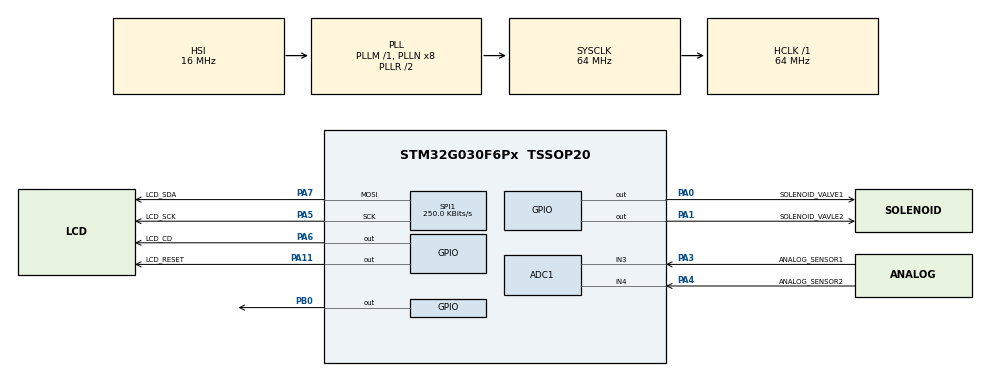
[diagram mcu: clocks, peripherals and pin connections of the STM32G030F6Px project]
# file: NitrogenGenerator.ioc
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ADC1.Channel-3\#ChannelRegularConversion=ADC_CHANNEL_3
ADC1.ClockPrescaler=ADC_CLOCK_ASYNC_DIV256
ADC1.ContinuousConvMode=DISABLE
ADC1.DMAContinuousRequests=DISABLE
ADC1.DiscontinuousConvMode=DISABLE
ADC1.EOCSelection=ADC_EOC_SINGLE_CONV
ADC1.NbrOfConversion=1
ADC1.NbrOfConversionFlag=1
ADC1.Rank-3\#ChannelRegularConversion=1
ADC1.SamplingTime-3\#ChannelRegularConversion=ADC_SAMPLINGTIME_COMMON_1
ADC1.SamplingTimeCommon1=ADC_SAMPLETIME_160CYCLES_5
ADC1.SamplingTimeCommon2=ADC_SAMPLETIME_160CYCLES_5
ADC1.SelectedChannel=ADC_CHANNEL_3|ADC_CHANNEL_4
ADC1.Sequencer=FULLY_CONFIGURABLE
ADC1.TriggerFrequencyMode=ADC_TRIGGER_FREQ_LOW
ADC1.master=1
Dma.ADC1.0.Direction=DMA_PERIPH_TO_MEMORY
Dma.ADC1.0.EventEnable=DISABLE
Dma.ADC1.0.Instance=DMA1_Channel1
Dma.ADC1.0.MemDataAlignment=DMA_MDATAALIGN_WORD
Dma.ADC1.0.MemInc=DMA_MINC_ENABLE
Dma.ADC1.0.Mode=DMA_NORMAL
Dma.ADC1.0.PeriphDataAlignment=DMA_PDATAALIGN_WORD
Dma.ADC1.0.PeriphInc=DMA_PINC_DISABLE
Dma.ADC1.0.Polarity=HAL_DMAMUX_REQ_GEN_RISING
Dma.ADC1.0.Priority=DMA_PRIORITY_LOW
Dma.ADC1.0.RequestNumber=1
Dma.ADC1.0.SignalID=NONE
Dma.ADC1.0.SyncEnable=DISABLE
Dma.ADC1.0.SyncPolarity=HAL_DMAMUX_SYNC_NO_EVENT
Dma.ADC1.0.SyncRequestNumber=1
Dma.ADC1.0.SyncSignalID=NONE
Dma.Request0=ADC1
Mcu.Family=STM32G0
Mcu.Name=STM32G030F6Px
Mcu.Package=TSSOP20
NVIC.ADC1_IRQn=true\:0\:0\:false\:false\:true\:true\:true\:true
NVIC.DMA1_Channel1_IRQn=true\:0\:0\:false\:false\:true\:false\:true\:true
NVIC.TIM1_BRK_UP_TRG_COM_IRQn=true\:0\:0\:false\:false\:true\:true\:true\:true
NVIC.TIM1_CC_IRQn=true\:0\:0\:false\:false\:true\:true\:true\:true
NVIC.TIM3_IRQn=true\:0\:0\:false\:false\:true\:true\:true\:true
PA0.GPIO_Label=SOLENOID_VALVE1
PA0.Signal=GPIO_Output
PA1.GPIO_Label=SOLENOID_VAVLE2
PA1.Signal=GPIO_Output
PA11\ [PA9].GPIO_Label=LCD_RESET
PA11\ [PA9].Signal=GPIO_Output
PA13.Mode=Serial_Wire
PA13.Signal=SYS_SWDIO
PA14-BOOT0.Mode=Serial_Wire
PA14-BOOT0.Signal=SYS_SWCLK
PA14-BOOT0__PA15.StandardMode=true
PA3.GPIO_Label=ANALOG_SENSOR1
PA3.Mode=IN3
PA3.Signal=ADC1_IN3
PA4.GPIO_Label=ANALOG_SENSOR2
PA4.Mode=IN4
PA4.Signal=ADC1_IN4
PA5.GPIO_Label=LCD_SCK
PA5.Mode=TX_Only_Simplex_Unidirect_Master
PA5.Signal=SPI1_SCK
PA6.GPIO_Label=LCD_CD
PA6.Signal=GPIO_Output
PA7.GPIO_Label=LCD_SDA
PA7.Mode=TX_Only_Simplex_Unidirect_Master
PA7.Signal=SPI1_MOSI
PB0.Signal=GPIO_Output
PB0__PB1__PB2__PA8.StandardMode=false
PB3__PB4__PB5__PB6.StandardMode=true
PB7__PB8.StandardMode=true
PC14-OSC32_IN\ (PC14)__PB9.StandardMode=true
ProjectManager.HeapSize=0x200
ProjectManager.StackSize=0x400
ProjectManager.TargetToolchain=CMake
RCC.ADCFreq_Value=64000000
RCC.AHBFreq_Value=64000000
RCC.CortexFreq_Value=64000000
RCC.EXTERNAL_CLOCK_VALUE=12288000
RCC.HCLKFreq_Value=64000000
RCC.HSE_VALUE=8000000
RCC.HSI_VALUE=16000000
RCC.LSE_VALUE=32768
RCC.PLLP=RCC_PLLP_DIV4
RCC.SYSCLKFreq_VALUE=64000000
RCC.SYSCLKSource=RCC_SYSCLKSOURCE_PLLCLK
RCC.VCOOutputFreq_Value=128000000
SPI1.BaudRatePrescaler=SPI_BAUDRATEPRESCALER_256
SPI1.CalculateBaudRate=250.0 KBits/s
SPI1.Direction=SPI_DIRECTION_2LINES
SPI1.Mode=SPI_MODE_MASTER
SPI1.VirtualType=VM_MASTER
TIM1.AutoReloadPreload=TIM_AUTORELOAD_PRELOAD_ENABLE
TIM1.Period=64000
TIM1.Prescaler=100
TIM3.AutoReloadPreload=TIM_AUTORELOAD_PRELOAD_ENABLE
TIM3.Period=64000
TIM3.Prescaler=1000
VP_TIM1_VS_ClockSourceINT.Mode=Internal
VP_TIM3_VS_ClockSourceINT.Mode=Internal
board=custom

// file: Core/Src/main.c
/* USER CODE BEGIN Header */
/**
  ******************************************************************************
  * @file           : main.c
  * @brief          : Main program body
  ******************************************************************************
  * @attention
  *
  * Copyright (c) 2025 STMicroelectronics.
  * All rights reserved.
  *
  * This software is licensed under terms that can be found in the LICENSE file
  * in the root directory of this software component.
  * If no LICENSE file comes with this software, it is provided AS-IS.
  *
  ******************************************************************************
  */
/* USER CODE END Header */
#include "main.h"

/* USER CODE BEGIN Includes */
#include <string.h>
#include "../../screen.h"
/* USER CODE END Includes */

ADC_HandleTypeDef hadc1;
DMA_HandleTypeDef hdma_adc1;

SPI_HandleTypeDef hspi1;

TIM_HandleTypeDef htim1;
TIM_HandleTypeDef htim3;

void SystemClock_Config(void);
static void MX_GPIO_Init(void);
static void MX_DMA_Init(void);
static void MX_ADC1_Init(void);
static void MX_SPI1_Init(void);
static void MX_TIM1_Init(void);
static void MX_TIM3_Init(void);

int main(void)
{

  /* MCU Configuration--------------------------------------------------------*/

  /* Reset of all peripherals, Initializes the Flash interface and the Systick. */
  HAL_Init();

  /* Configure the system clock */
  SystemClock_Config();

  /* Initialize all configured peripherals */
  MX_GPIO_Init();
  MX_DMA_Init();
  MX_ADC1_Init();
  MX_SPI1_Init();
  MX_TIM1_Init();
  MX_TIM3_Init();
  /* USER CODE BEGIN 2 */
  screen_init();
  HAL_ADCEx_Calibration_Start(&hadc1);
  HAL_TIM_Base_Start_IT(&htim1);
  HAL_TIM_Base_Start_IT(&htim3);
  /* USER CODE END 2 */

  /* Infinite loop */
  /* USER CODE BEGIN WHILE */
  while (1)
  {
    __WFI();
    /* USER CODE END WHILE */

  }
}

void SystemClock_Config(void)
{
  RCC_OscInitTypeDef RCC_OscInitStruct = {0};
  RCC_ClkInitTypeDef RCC_ClkInitStruct = {0};

  /** Configure the main internal regulator output voltage
  */
  HAL_PWREx_ControlVoltageScaling(PWR_REGULATOR_VOLTAGE_SCALE1);

  /** Initializes the RCC Oscillators according to the specified parameters
  * in the RCC_OscInitTypeDef structure.
  */
  RCC_OscInitStruct.OscillatorType = RCC_OSCILLATORTYPE_HSI;
  RCC_OscInitStruct.HSIState = RCC_HSI_ON;
  RCC_OscInitStruct.HSIDiv = RCC_HSI_DIV1;
  RCC_OscInitStruct.HSICalibrationValue = RCC_HSICALIBRATION_DEFAULT;
  RCC_OscInitStruct.PLL.PLLState = RCC_PLL_ON;
  RCC_OscInitStruct.PLL.PLLSource = RCC_PLLSOURCE_HSI;
  RCC_OscInitStruct.PLL.PLLM = RCC_PLLM_DIV1;
  RCC_OscInitStruct.PLL.PLLN = 8;
  RCC_OscInitStruct.PLL.PLLP = RCC_PLLP_DIV4;
  RCC_OscInitStruct.PLL.PLLR = RCC_PLLR_DIV2;
  if (HAL_RCC_OscConfig(&RCC_OscInitStruct) != HAL_OK)
  {
    Error_Handler();
  }

  /** Initializes the CPU, AHB and APB buses clocks
  */
  RCC_ClkInitStruct.ClockType = RCC_CLOCKTYPE_HCLK|RCC_CLOCKTYPE_SYSCLK
                              |RCC_CLOCKTYPE_PCLK1;
  RCC_ClkInitStruct.SYSCLKSource = RCC_SYSCLKSOURCE_PLLCLK;
  RCC_ClkInitStruct.AHBCLKDivider = RCC_SYSCLK_DIV1;
  RCC_ClkInitStruct.APB1CLKDivider = RCC_HCLK_DIV1;

  if (HAL_RCC_ClockConfig(&RCC_ClkInitStruct, FLASH_LATENCY_2) != HAL_OK)
  {
    Error_Handler();
  }
}

static void MX_ADC1_Init(void)
{

  ADC_ChannelConfTypeDef sConfig = {0};

  /** Configure the global features of the ADC (Clock, Resolution, Data Alignment and number of conversion)
  */
  hadc1.Instance = ADC1;
  hadc1.Init.ClockPrescaler = ADC_CLOCK_ASYNC_DIV256;
  hadc1.Init.Resolution = ADC_RESOLUTION_12B;
  hadc1.Init.DataAlign = ADC_DATAALIGN_RIGHT;
  hadc1.Init.ScanConvMode = ADC_SCAN_DISABLE;
  hadc1.Init.EOCSelection = ADC_EOC_SINGLE_CONV;
  hadc1.Init.LowPowerAutoWait = DISABLE;
  hadc1.Init.LowPowerAutoPowerOff = DISABLE;
  hadc1.Init.ContinuousConvMode = DISABLE;
  hadc1.Init.NbrOfConversion = 1;
  hadc1.Init.DiscontinuousConvMode = DISABLE;
  hadc1.Init.ExternalTrigConv = ADC_SOFTWARE_START;
  hadc1.Init.ExternalTrigConvEdge = ADC_EXTERNALTRIGCONVEDGE_NONE;
  hadc1.Init.DMAContinuousRequests = DISABLE;
  hadc1.Init.Overrun = ADC_OVR_DATA_PRESERVED;
  hadc1.Init.SamplingTimeCommon1 = ADC_SAMPLETIME_160CYCLES_5;
  hadc1.Init.SamplingTimeCommon2 = ADC_SAMPLETIME_160CYCLES_5;
  hadc1.Init.OversamplingMode = DISABLE;
  hadc1.Init.TriggerFrequencyMode = ADC_TRIGGER_FREQ_LOW;
  if (HAL_ADC_Init(&hadc1) != HAL_OK)
  {
    Error_Handler();
  }

  /** Configure Regular Channel
  */
  sConfig.Channel = ADC_CHANNEL_3;
  sConfig.Rank = ADC_REGULAR_RANK_1;
  sConfig.SamplingTime = ADC_SAMPLINGTIME_COMMON_1;
  if (HAL_ADC_ConfigChannel(&hadc1, &sConfig) != HAL_OK)
  {
    Error_Handler();
  }

}

static void MX_SPI1_Init(void)
{

  /* SPI1 parameter configuration*/
  hspi1.Instance = SPI1;
  hspi1.Init.Mode = SPI_MODE_MASTER;
  hspi1.Init.Direction = SPI_DIRECTION_2LINES;
  hspi1.Init.DataSize = SPI_DATASIZE_8BIT;
  hspi1.Init.CLKPolarity = SPI_POLARITY_LOW;
  hspi1.Init.CLKPhase = SPI_PHASE_1EDGE;
  hspi1.Init.NSS = SPI_NSS_SOFT;
  hspi1.Init.BaudRatePrescaler = SPI_BAUDRATEPRESCALER_256;
  hspi1.Init.FirstBit = SPI_FIRSTBIT_MSB;
  hspi1.Init.TIMode = SPI_TIMODE_DISABLE;
  hspi1.Init.CRCCalculation = SPI_CRCCALCULATION_DISABLE;
  hspi1.Init.CRCPolynomial = 7;
  hspi1.Init.CRCLength = SPI_CRC_LENGTH_DATASIZE;
  hspi1.Init.NSSPMode = SPI_NSS_PULSE_ENABLE;
  if (HAL_SPI_Init(&hspi1) != HAL_OK)
  {
    Error_Handler();
  }

}

static void MX_TIM1_Init(void)
{

  TIM_ClockConfigTypeDef sClockSourceConfig = {0};
  TIM_MasterConfigTypeDef sMasterConfig = {0};

  htim1.Instance = TIM1;
  htim1.Init.Prescaler = 100;
  htim1.Init.CounterMode = TIM_COUNTERMODE_UP;
  htim1.Init.Period = 64000;
  htim1.Init.ClockDivision = TIM_CLOCKDIVISION_DIV1;
  htim1.Init.RepetitionCounter = 0;
  htim1.Init.AutoReloadPreload = TIM_AUTORELOAD_PRELOAD_ENABLE;
  if (HAL_TIM_Base_Init(&htim1) != HAL_OK)
  {
    Error_Handler();
  }
  sClockSourceConfig.ClockSource = TIM_CLOCKSOURCE_INTERNAL;
  if (HAL_TIM_ConfigClockSource(&htim1, &sClockSourceConfig) != HAL_OK)
  {
    Error_Handler();
  }
  sMasterConfig.MasterOutputTrigger = TIM_TRGO_RESET;
  sMasterConfig.MasterOutputTrigger2 = TIM_TRGO2_RESET;
  sMasterConfig.MasterSlaveMode = TIM_MASTERSLAVEMODE_DISABLE;
  if (HAL_TIMEx_MasterConfigSynchronization(&htim1, &sMasterConfig) != HAL_OK)
  {
    Error_Handler();
  }

}

static void MX_TIM3_Init(void)
{

  TIM_ClockConfigTypeDef sClockSourceConfig = {0};
  TIM_MasterConfigTypeDef sMasterConfig = {0};

  htim3.Instance = TIM3;
  htim3.Init.Prescaler = 1000;
  htim3.Init.CounterMode = TIM_COUNTERMODE_UP;
  htim3.Init.Period = 64000;
  htim3.Init.ClockDivision = TIM_CLOCKDIVISION_DIV1;
  htim3.Init.AutoReloadPreload = TIM_AUTORELOAD_PRELOAD_ENABLE;
  if (HAL_TIM_Base_Init(&htim3) != HAL_OK)
  {
    Error_Handler();
  }
  sClockSourceConfig.ClockSource = TIM_CLOCKSOURCE_INTERNAL;
  if (HAL_TIM_ConfigClockSource(&htim3, &sClockSourceConfig) != HAL_OK)
  {
    Error_Handler();
  }
  sMasterConfig.MasterOutputTrigger = TIM_TRGO_RESET;
  sMasterConfig.MasterSlaveMode = TIM_MASTERSLAVEMODE_DISABLE;
  if (HAL_TIMEx_MasterConfigSynchronization(&htim3, &sMasterConfig) != HAL_OK)
  {
    Error_Handler();
  }

}

static void MX_DMA_Init(void)
{

  /* DMA controller clock enable */
  __HAL_RCC_DMA1_CLK_ENABLE();

  /* DMA interrupt init */
  /* DMA1_Channel1_IRQn interrupt configuration */
  HAL_NVIC_SetPriority(DMA1_Channel1_IRQn, 0, 0);
  HAL_NVIC_EnableIRQ(DMA1_Channel1_IRQn);

}

static void MX_GPIO_Init(void)
{
  GPIO_InitTypeDef GPIO_InitStruct = {0};

  /* GPIO Ports Clock Enable */
  __HAL_RCC_GPIOB_CLK_ENABLE();
  __HAL_RCC_GPIOC_CLK_ENABLE();
  __HAL_RCC_GPIOA_CLK_ENABLE();

  /*Configure GPIO pin Output Level */
  HAL_GPIO_WritePin(GPIOA, SOLENOID_VALVE1_Pin|SOLENOID_VAVLE2_Pin|LCD_CD_Pin|LCD_RESET_Pin, GPIO_PIN_RESET);

  /*Configure GPIO pin Output Level */
  HAL_GPIO_WritePin(GPIOB, GPIO_PIN_0, GPIO_PIN_RESET);

  /*Configure GPIO pins : PB7 PB8 PB9 PB1
                           PB2 PB3 PB4 PB5
                           PB6 */
  GPIO_InitStruct.Pin = GPIO_PIN_7|GPIO_PIN_8|GPIO_PIN_9|GPIO_PIN_1
                          |GPIO_PIN_2|GPIO_PIN_3|GPIO_PIN_4|GPIO_PIN_5
                          |GPIO_PIN_6;
  GPIO_InitStruct.Mode = GPIO_MODE_ANALOG;
  GPIO_InitStruct.Pull = GPIO_NOPULL;
  HAL_GPIO_Init(GPIOB, &GPIO_InitStruct);

  /*Configure GPIO pins : PC14 PC15 */
  GPIO_InitStruct.Pin = GPIO_PIN_14|GPIO_PIN_15;
  GPIO_InitStruct.Mode = GPIO_MODE_ANALOG;
  GPIO_InitStruct.Pull = GPIO_NOPULL;
  HAL_GPIO_Init(GPIOC, &GPIO_InitStruct);

  /*Configure GPIO pins : SOLENOID_VALVE1_Pin SOLENOID_VAVLE2_Pin LCD_CD_Pin LCD_RESET_Pin */
  GPIO_InitStruct.Pin = SOLENOID_VALVE1_Pin|SOLENOID_VAVLE2_Pin|LCD_CD_Pin|LCD_RESET_Pin;
  GPIO_InitStruct.Mode = GPIO_MODE_OUTPUT_PP;
  GPIO_InitStruct.Pull = GPIO_NOPULL;
  GPIO_InitStruct.Speed = GPIO_SPEED_FREQ_LOW;
  HAL_GPIO_Init(GPIOA, &GPIO_InitStruct);

  /*Configure GPIO pins : PA2 PA8 PA12 PA15 */
  GPIO_InitStruct.Pin = GPIO_PIN_2|GPIO_PIN_8|GPIO_PIN_12|GPIO_PIN_15;
  GPIO_InitStruct.Mode = GPIO_MODE_ANALOG;
  GPIO_InitStruct.Pull = GPIO_NOPULL;
  HAL_GPIO_Init(GPIOA, &GPIO_InitStruct);

  /*Configure GPIO pin : PB0 */
  GPIO_InitStruct.Pin = GPIO_PIN_0;
  GPIO_InitStruct.Mode = GPIO_MODE_OUTPUT_PP;
  GPIO_InitStruct.Pull = GPIO_NOPULL;
  GPIO_InitStruct.Speed = GPIO_SPEED_FREQ_LOW;
  HAL_GPIO_Init(GPIOB, &GPIO_InitStruct);

}

void Error_Handler(void)
{
  __disable_irq();
  while (1)
  {
  }
}
